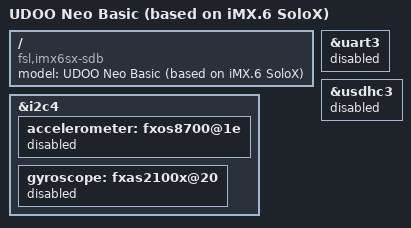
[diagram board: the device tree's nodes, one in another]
/*
 * Copyright (C) 2015 Jasbir Matharu
 * Author: Ettore Chimenti <ek5.chimenti@gmail.com>
 *
 * This program is free software; you can redistribute it and/or modify
 * it under the terms of the GNU General Public License version 2 as
 * published by the Free Software Foundation.
 */


/ {
	model = "UDOO Neo Basic (based on iMX.6 SoloX)";
	compatible = "fsl,imx6sx-sdb", "fsl,imx6sx";
	
};

&uart3 { /* Bluetooth */
	status = "disabled";
};

&usdhc3 { /* WiFi */
	status = "disabled";
};

&i2c4 {
	accelerometer: fxos8700@1e {
		status = "disabled";
	};
	gyroscope: fxas2100x@20 {
		status = "disabled";
	};
};
